# apollo4p register map
Vendor: Ambiq Micro; Series: Apollo; File version: 1.0
CPU: CM4 r1p0, little endian, MPU, FPU, I-cache, D-cache, VTOR, ITCM, DTCM, 3 interrupt priority bits, 0 interrupts
Registers are 32-bit, read-write, reset 0x0 unless marked. A register's access mark holds for its fields unless they carry their own. Offsets are from the block's base; [hi:lo] are bit positions; 'fields as' and 'values as' point back to an identical list.

## IOSLAVE — I2C/SPI Slave
Base 0x40034000
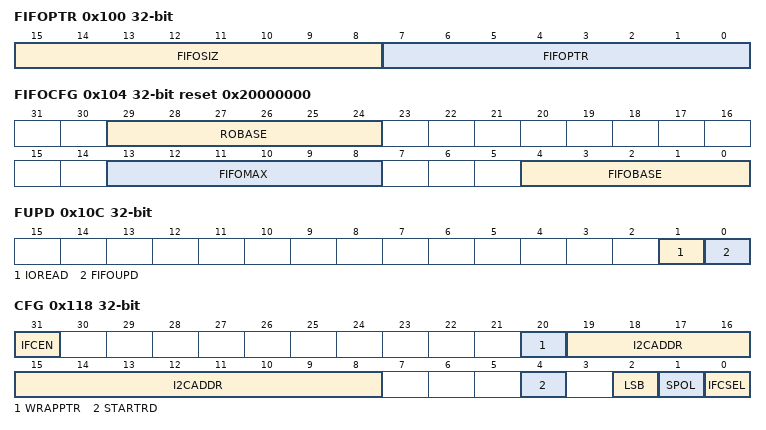
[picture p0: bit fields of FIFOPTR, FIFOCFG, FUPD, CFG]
0x100 FIFOPTR — Current FIFO Pointer
  [15:8] FIFOSIZ — The number of bytes currently in the hardware FIFO.
  [7:0] FIFOPTR — Current FIFO pointer.
0x104 FIFOCFG reset 0x20000000 — FIFO Configuration
  [29:24] ROBASE — Defines the read-only area. The IO Slave read-only area is situated in LRAM at (ROBASE*8) to (FIFOBASE*8-1)
  [13:8] FIFOMAX — These bits hold the maximum FIFO address in 8 byte segments. It is also the beginning of the RAM area of the LRAM. Note that no RAM area is configured if FIFOMAX is set to 0x1F.
  [4:0] FIFOBASE — These bits hold the base address of the I/O FIFO in 8 byte segments. The IO Slave FIFO is situated in LRAM at (FIFOBASE*8) to (FIFOMAX*8-1).
0x108 FIFOTHR — FIFO Threshold Configuration
  [7:0] FIFOTHR — FIFO size interrupt threshold.
0x10C FUPD — FIFO Update Status
  [1] IOREAD — This bitfield indicates an IO read is active.
  [0] FIFOUPD — This bit indicates that a FIFO update is underway.
0x110 FIFOCTR — Overall FIFO Counter
  [9:0] FIFOCTR — Virtual FIFO byte count
0x114 FIFOINC — Overall FIFO Counter Increment
  [9:0] FIFOINC — Increment the Overall FIFO Counter by this value on a write
0x118 CFG — I/O Slave Configuration
  [31] IFCEN — IOSLAVE interface enable.
    0=DIS (Disable the IOSLAVE); 1=EN (Enable the IOSLAVE)
  [20] WRAPPTR — Address pointer wrap mode enable.
    0=NOWRAP (Address pointer does not wrap around to FIFOBASE*8 after it reaches FIFOMAX*8-1. Additionally, the address pointer does not automatically skip Direct Area locations 0x78 to 0x7F, so care must be taken that the host does not inadvertently write to the Host Registers during a data transfer.); 1=WRAP (Address pointer wraps around to FIFOBASE*8 after it reaches FIFOMAX*8-1 to accommodate any length transfers. In addition, the address pointer automatically skips Direct Area locations 0x78 to 0x7F (if the FIFO Area encompasses these locations) to avoid writing to the Host Registers.)
  [19:8] I2CADDR — 7-bit or 10-bit I2C device address.
  [4] STARTRD — This bit holds the cycle to initiate an I/O RAM read.
    0=LATE (Initiate I/O RAM read late in each transferred byte.); 1=EARLY (Initiate I/O RAM read early in each transferred byte.)
  [2] LSB — This bit selects the transfer bit ordering.
    0=MSB_FIRST (Data is assumed to be sent and received with MSB first.); 1=LSB_FIRST (Data is assumed to be sent and received with LSB first.)
  [1] SPOL — This bit selects SPI polarity.
    0=SPI_MODES_0_3 (Polarity 0, handles SPI modes 0 and 3.); 1=SPI_MODES_1_2 (Polarity 1, handles SPI modes 1 and 2.)
  [0] IFCSEL — This bit selects the I/O interface.
    0=I2C (Selects I2C interface for the IO Slave.); 1=SPI (Selects SPI interface for the IO Slave.)
0x11C PRENC — I/O Slave Interrupt Priority Encode
  [4:0] PRENC — These bits hold the priority encode of the REGACC interrupts.
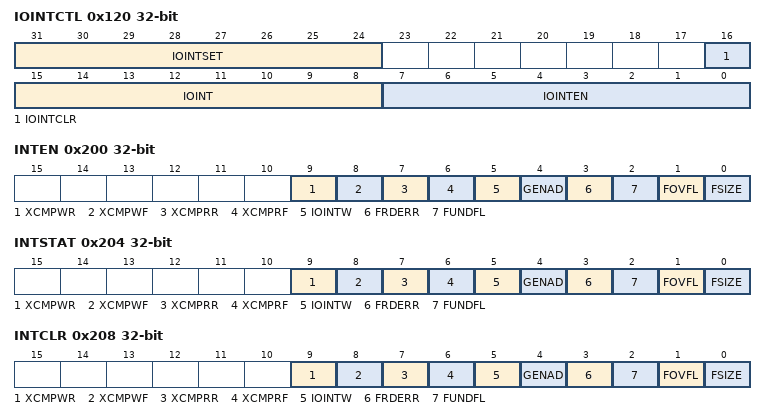
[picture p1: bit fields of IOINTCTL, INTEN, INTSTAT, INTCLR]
0x120 IOINTCTL — I/O Interrupt Control
  [31:24] IOINTSET — These bits set the IOINT interrupts when written with a 1.
  [16] IOINTCLR — This bit clears all of the IOINT interrupts when written with a 1.
  [15:8] IOINT — These bits read the IOINT interrupts.
  [7:0] IOINTEN — These read-only bits indicate whether the IOINT interrupts are enabled.
0x124 GENADD — General Address Data
  [7:0] GADATA — The data supplied on the last General Address reference.
0x128 ADDPTR — Address pointer
  [7:0] ADDPTR — The current value in the Address pointer.
0x200 INTEN — Set bits in this register to allow this module to generate the corresponding interrupt.
  [9] XCMPWR — Transfer complete interrupt, write to register space.
  [8] XCMPWF — Transfer complete interrupt, write to FIFO space.
  [7] XCMPRR — Transfer complete interrupt, read from register space.
  [6] XCMPRF — Transfer complete interrupt, read from FIFO space.
  [5] IOINTW — IO Write interrupt.
  [4] GENAD — I2C General Address interrupt.
  [3] FRDERR — FIFO Read Error interrupt.
  [2] FUNDFL — FIFO Underflow interrupt.
  [1] FOVFL — FIFO Overflow interrupt.
  [0] FSIZE — FIFO Size interrupt.
0x204 INTSTAT — Read bits from this register to discover the cause of a recent interrupt.
  fields as INTEN
0x208 INTCLR — Write a 1 to a bit in this register to clear the interrupt status associated with that bit.
  fields as INTEN
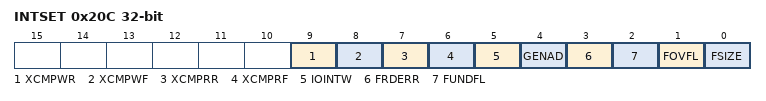
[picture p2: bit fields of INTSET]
0x20C INTSET — Write a 1 to a bit in this register to instantly generate an interrupt from this module. (Generally used for testing purposes).
  fields as INTEN
0x210 REGACCINTEN — Set bits in this register to allow this module to generate the corresponding interrupt.
  [31:0] REGACC — Register access interrupts.
0x214 REGACCINTSTAT — Read bits from this register to discover the cause of a recent interrupt.
  [31:0] REGACC — Register access interrupts.
0x218 REGACCINTCLR — Write a 1 to a bit in this register to clear the interrupt status associated with that bit.
  [31:0] REGACC — Register access interrupts.
0x21C REGACCINTSET — Write a 1 to a bit in this register to instantly generate an interrupt from this module. (Generally used for testing purposes).
  [31:0] REGACC — Register access interrupts.
